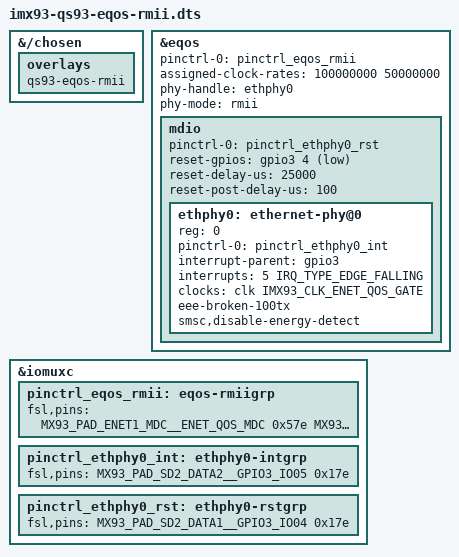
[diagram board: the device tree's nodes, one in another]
// SPDX-License-Identifier: (GPL-2.0 OR MIT)
/*
 * Copyright 2023 Lothar Waßmann <LW@KARO-electronics.de>
 *
 */

/dts-v1/;

/plugin/;

&{/chosen} {
	overlays {
		qs93-eqos-rmii;
	};
};

&eqos {
	pinctrl-0 = <&pinctrl_eqos_rmii>;
	assigned-clock-rates = <100000000 50000000>;
	phy-handle = <&ethphy0>;
	phy-mode = "rmii";
#if 0
	phy-reset-gpios = <&gpio3 4 GPIO_ACTIVE_LOW>;
	phy-reset-duration = <25>;
	phy-reset-post-delay = <1>;
#endif
	status = "okay";

	mdio {
		pinctrl-names = "default";
		pinctrl-0 = <&pinctrl_ethphy0_rst>;
#if 1
		reset-gpios = <&gpio3 4 GPIO_ACTIVE_LOW>;
		reset-delay-us = <25000>;
		reset-post-delay-us = <100>;
#endif
		ethphy0: ethernet-phy@0 {
			reg = <0>;
			pinctrl-names = "default";
			pinctrl-0 = <&pinctrl_ethphy0_int>;
			interrupt-parent = <&gpio3>;
			interrupts = <5 IRQ_TYPE_EDGE_FALLING>;
			clocks = <&clk IMX93_CLK_ENET_QOS_GATE>;
			eee-broken-100tx;
			smsc,disable-energy-detect;
		};
	};
};

&iomuxc {
	pinctrl_eqos_rmii: eqos-rmiigrp {
		fsl,pins = <
			MX93_PAD_ENET1_MDC__ENET_QOS_MDC			0x57e
			MX93_PAD_ENET1_MDIO__ENET_QOS_MDIO			0x17e
			MX93_PAD_ENET1_TD2__CCM_ENET_QOS_CLOCK_GENERATE_REF_CLK	0x4000017e
			/* Strap pins: MODE0 HIGH: 0x3.. LOW: 0x5.. */
			MX93_PAD_ENET1_RD0__ENET_QOS_RGMII_RD0			0x37e
			/* MODE1 */
			MX93_PAD_ENET1_RD1__ENET_QOS_RGMII_RD1			0x37e
			/* MODE2 (external pullup) */
			MX93_PAD_ENET1_RX_CTL__ENET_QOS_RGMII_RX_CTL		0x37e
			/* PHYAD0 */
			MX93_PAD_ENET1_RXC__ENET_QOS_RX_ER			0x37e

			MX93_PAD_ENET1_TD0__ENET_QOS_RGMII_TD0			0x57e
			MX93_PAD_ENET1_TD1__ENET_QOS_RGMII_TD1			0x57e
			MX93_PAD_ENET1_TX_CTL__ENET_QOS_RGMII_TX_CTL		0x57e
		>;
	};

	pinctrl_ethphy0_int: ethphy0-intgrp {
		fsl,pins = <
			MX93_PAD_SD2_DATA2__GPIO3_IO05				0x17e
		>;
	};

	pinctrl_ethphy0_rst: ethphy0-rstgrp {
		fsl,pins = <
			MX93_PAD_SD2_DATA1__GPIO3_IO04				0x17e
		>;
	};
};
